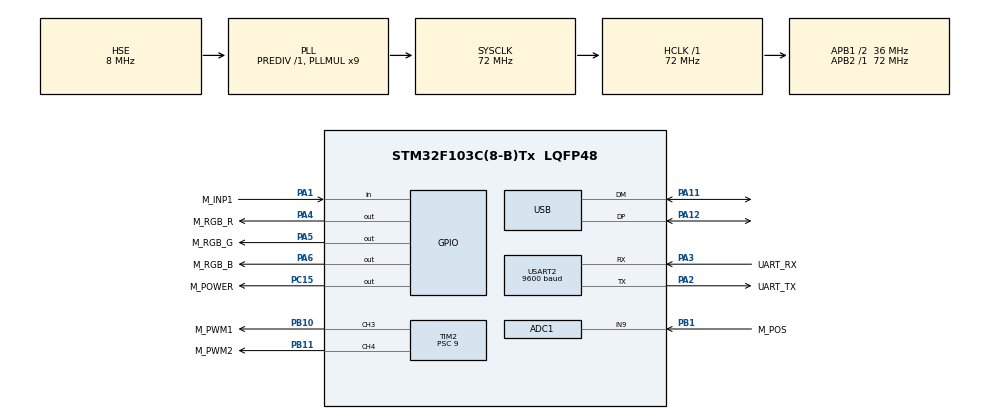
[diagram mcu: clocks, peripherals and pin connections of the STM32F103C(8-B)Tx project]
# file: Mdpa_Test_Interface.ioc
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ADC1.Channel-0\#ChannelRegularConversion=ADC_CHANNEL_9
ADC1.NbrOfConversionFlag=1
ADC1.Rank-0\#ChannelRegularConversion=1
ADC1.SamplingTime-0\#ChannelRegularConversion=ADC_SAMPLETIME_1CYCLE_5
ADC1.master=1
Dma.Request0=USART2_RX
Dma.USART2_RX.0.Direction=DMA_PERIPH_TO_MEMORY
Dma.USART2_RX.0.Instance=DMA1_Channel6
Dma.USART2_RX.0.MemDataAlignment=DMA_MDATAALIGN_BYTE
Dma.USART2_RX.0.MemInc=DMA_MINC_ENABLE
Dma.USART2_RX.0.Mode=DMA_CIRCULAR
Dma.USART2_RX.0.PeriphDataAlignment=DMA_PDATAALIGN_BYTE
Dma.USART2_RX.0.PeriphInc=DMA_PINC_DISABLE
Dma.USART2_RX.0.Priority=DMA_PRIORITY_HIGH
FREERTOS.Tasks01=defaultTask,0,128,StartDefaultTask,Default,NULL,Dynamic,NULL,NULL
Mcu.Family=STM32F1
Mcu.Name=STM32F103C(8-B)Tx
Mcu.Package=LQFP48
NVIC.ADC1_2_IRQn=true\:5\:0\:false\:false\:true\:true\:true\:true\:true
NVIC.DMA1_Channel6_IRQn=true\:5\:0\:false\:false\:true\:true\:false\:true\:true
NVIC.PriorityGroup=NVIC_PRIORITYGROUP_4
NVIC.TIM4_IRQn=true\:15\:0\:false\:false\:true\:false\:false\:true\:true
NVIC.TimeBase=TIM4_IRQn
NVIC.TimeBaseIP=TIM4
NVIC.USART2_IRQn=true\:5\:0\:false\:false\:true\:true\:true\:true\:true
NVIC.USB_LP_CAN1_RX0_IRQn=true\:5\:0\:false\:false\:true\:true\:false\:true\:true
PA1.GPIO_Label=M_INP1
PA1.GPIO_PuPd=GPIO_PULLUP
PA1.Signal=GPIO_Input
PA11.Mode=Device
PA11.Signal=USB_DM
PA12.Mode=Device
PA12.Signal=USB_DP
PA13.Mode=Serial_Wire
PA13.Signal=SYS_JTMS-SWDIO
PA14.Mode=Serial_Wire
PA14.Signal=SYS_JTCK-SWCLK
PA2.GPIO_Label=UART_TX
PA2.Mode=Asynchronous
PA2.Signal=USART2_TX
PA3.GPIO_Label=UART_RX
PA3.GPIO_PuPd=GPIO_PULLUP
PA3.Mode=Asynchronous
PA3.Signal=USART2_RX
PA4.GPIO_Label=M_RGB_R
PA4.Signal=GPIO_Output
PA5.GPIO_Label=M_RGB_G
PA5.Signal=GPIO_Output
PA6.GPIO_Label=M_RGB_B
PA6.Signal=GPIO_Output
PB1.GPIO_Label=M_POS
PB1.Signal=ADCx_IN9
PB10.GPIO_Label=M_PWM1
PB10.Signal=S_TIM2_CH3
PB11.GPIO_Label=M_PWM2
PB11.Signal=S_TIM2_CH4
PC15-OSC32_OUT.GPIO_Label=M_POWER
PC15-OSC32_OUT.Signal=GPIO_Output
PD0-OSC_IN.Mode=HSE-External-Oscillator
PD0-OSC_IN.Signal=RCC_OSC_IN
PD1-OSC_OUT.Mode=HSE-External-Oscillator
PD1-OSC_OUT.Signal=RCC_OSC_OUT
ProjectManager.HeapSize=0x200
ProjectManager.StackSize=0x400
ProjectManager.TargetToolchain=MDK-ARM V5.32
RCC.ADCPresc=RCC_ADCPCLK2_DIV6
RCC.AHBFreq_Value=72000000
RCC.APB1CLKDivider=RCC_HCLK_DIV2
RCC.APB1Freq_Value=36000000
RCC.APB1TimFreq_Value=72000000
RCC.APB2Freq_Value=72000000
RCC.APB2TimFreq_Value=72000000
RCC.HCLKFreq_Value=72000000
RCC.PLLMUL=RCC_PLL_MUL9
RCC.PLLSourceVirtual=RCC_PLLSOURCE_HSE
RCC.SYSCLKFreq_VALUE=72000000
RCC.SYSCLKSource=RCC_SYSCLKSOURCE_PLLCLK
RCC.USBFreq_Value=48000000
RCC.USBPrescaler=RCC_USBCLKSOURCE_PLL_DIV1_5
SH.ADCx_IN9.0=ADC1_IN9,IN9
SH.S_TIM2_CH3.0=TIM2_CH3,PWM Generation3 CH3
SH.S_TIM2_CH4.0=TIM2_CH4,PWM Generation4 CH4
TIM2.Channel-PWM\ Generation3\ CH3=TIM_CHANNEL_3
TIM2.Channel-PWM\ Generation4\ CH4=TIM_CHANNEL_4
TIM2.Period=359
TIM2.Prescaler=9
USART2.BaudRate=9600
USART2.VirtualMode=VM_ASYNC
USB_DEVICE.CLASS_NAME_FS=CDC
USB_DEVICE.VirtualMode=Cdc
USB_DEVICE.VirtualModeFS=Cdc_FS
VP_FREERTOS_VS_CMSIS_V1.Mode=CMSIS_V1
VP_SYS_VS_tim4.Mode=TIM4
VP_USB_DEVICE_VS_USB_DEVICE_CDC_FS.Mode=CDC_FS
board=custom

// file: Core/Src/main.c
/* USER CODE BEGIN Header */
/**
  ******************************************************************************
  * @file           : main.c
  * @brief          : Main program body
  ******************************************************************************
  * @attention
  *
  * Copyright (c) 2022 STMicroelectronics.
  * All rights reserved.
  *
  * This software is licensed under terms that can be found in the LICENSE file
  * in the root directory of this software component.
  * If no LICENSE file comes with this software, it is provided AS-IS.
  *
  ******************************************************************************
  */
/* USER CODE END Header */
#include "main.h"
#include "cmsis_os.h"
#include "adc.h"
#include "dma.h"
#include "tim.h"
#include "usart.h"
#include "usb_device.h"
#include "gpio.h"

/* USER CODE BEGIN Includes */
#include "swl_Application.h"
/* USER CODE END Includes */

/* USER CODE BEGIN PV */
uint8_t buffer[64];
/* USER CODE END PV */

void SystemClock_Config(void);
void MX_FREERTOS_Init(void);

int main(void)
{

  /* MCU Configuration--------------------------------------------------------*/

  /* Reset of all peripherals, Initializes the Flash interface and the Systick. */
	HAL_Init();

  /* Configure the system clock */
  SystemClock_Config();

  /* Initialize all configured peripherals */
  MX_GPIO_Init();
  MX_DMA_Init();
  MX_TIM2_Init();
  MX_USART2_UART_Init();
  MX_ADC1_Init();
  /* USER CODE BEGIN 2 */
  swl_InitApplication();
  /* USER CODE END 2 */

  /* Call init function for freertos objects (in freertos.c) */
  MX_FREERTOS_Init();
  /* Start scheduler */
  osKernelStart();

  /* We should never get here as control is now taken by the scheduler */
  /* Infinite loop */
  while (1)
  {

  }
}

void SystemClock_Config(void)
{
  RCC_OscInitTypeDef RCC_OscInitStruct = {0};
  RCC_ClkInitTypeDef RCC_ClkInitStruct = {0};
  RCC_PeriphCLKInitTypeDef PeriphClkInit = {0};

  /** Initializes the RCC Oscillators according to the specified parameters
  * in the RCC_OscInitTypeDef structure.
  */
  RCC_OscInitStruct.OscillatorType = RCC_OSCILLATORTYPE_HSE;
  RCC_OscInitStruct.HSEState = RCC_HSE_ON;
  RCC_OscInitStruct.HSEPredivValue = RCC_HSE_PREDIV_DIV1;
  RCC_OscInitStruct.HSIState = RCC_HSI_ON;
  RCC_OscInitStruct.PLL.PLLState = RCC_PLL_ON;
  RCC_OscInitStruct.PLL.PLLSource = RCC_PLLSOURCE_HSE;
  RCC_OscInitStruct.PLL.PLLMUL = RCC_PLL_MUL9;
  if (HAL_RCC_OscConfig(&RCC_OscInitStruct) != HAL_OK)
  {
    Error_Handler();
  }
  /** Initializes the CPU, AHB and APB buses clocks
  */
  RCC_ClkInitStruct.ClockType = RCC_CLOCKTYPE_HCLK|RCC_CLOCKTYPE_SYSCLK
                              |RCC_CLOCKTYPE_PCLK1|RCC_CLOCKTYPE_PCLK2;
  RCC_ClkInitStruct.SYSCLKSource = RCC_SYSCLKSOURCE_PLLCLK;
  RCC_ClkInitStruct.AHBCLKDivider = RCC_SYSCLK_DIV1;
  RCC_ClkInitStruct.APB1CLKDivider = RCC_HCLK_DIV2;
  RCC_ClkInitStruct.APB2CLKDivider = RCC_HCLK_DIV1;

  if (HAL_RCC_ClockConfig(&RCC_ClkInitStruct, FLASH_LATENCY_2) != HAL_OK)
  {
    Error_Handler();
  }
  PeriphClkInit.PeriphClockSelection = RCC_PERIPHCLK_ADC|RCC_PERIPHCLK_USB;
  PeriphClkInit.AdcClockSelection = RCC_ADCPCLK2_DIV6;
  PeriphClkInit.UsbClockSelection = RCC_USBCLKSOURCE_PLL_DIV1_5;
  if (HAL_RCCEx_PeriphCLKConfig(&PeriphClkInit) != HAL_OK)
  {
    Error_Handler();
  }
}

void HAL_TIM_PeriodElapsedCallback(TIM_HandleTypeDef *htim)
{
  if (htim->Instance == TIM4) {
    HAL_IncTick();
  }
}

void Error_Handler(void)
{
  __disable_irq();
  while (1)
  {
  }
}

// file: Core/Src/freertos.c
/* USER CODE BEGIN Header */
/**
  ******************************************************************************
  * File Name          : freertos.c
  * Description        : Code for freertos applications
  ******************************************************************************
  * @attention
  *
  * Copyright (c) 2022 STMicroelectronics.
  * All rights reserved.
  *
  * This software is licensed under terms that can be found in the LICENSE file
  * in the root directory of this software component.
  * If no LICENSE file comes with this software, it is provided AS-IS.
  *
  ******************************************************************************
  */
/* USER CODE END Header */

#include "FreeRTOS.h"
#include "task.h"
#include "main.h"
#include "cmsis_os.h"

osThreadId defaultTaskHandle;

void StartDefaultTask(void const * argument);

extern void MX_USB_DEVICE_Init(void);
void MX_FREERTOS_Init(void); /* (MISRA C 2004 rule 8.1) */

/* GetIdleTaskMemory prototype (linked to static allocation support) */
void vApplicationGetIdleTaskMemory( StaticTask_t **ppxIdleTaskTCBBuffer, StackType_t **ppxIdleTaskStackBuffer, uint32_t *pulIdleTaskStackSize );

/* USER CODE BEGIN GET_IDLE_TASK_MEMORY */
static StaticTask_t xIdleTaskTCBBuffer;
static StackType_t xIdleStack[configMINIMAL_STACK_SIZE];

void vApplicationGetIdleTaskMemory( StaticTask_t **ppxIdleTaskTCBBuffer, StackType_t **ppxIdleTaskStackBuffer, uint32_t *pulIdleTaskStackSize )
{
  *ppxIdleTaskTCBBuffer = &xIdleTaskTCBBuffer;
  *ppxIdleTaskStackBuffer = &xIdleStack[0];
  *pulIdleTaskStackSize = configMINIMAL_STACK_SIZE;
  /* place for user code */
}
/* USER CODE END GET_IDLE_TASK_MEMORY */

void MX_FREERTOS_Init(void) {

  /* Create the thread(s) */
  /* definition and creation of defaultTask */
  osThreadDef(defaultTask, StartDefaultTask, osPriorityNormal, 0, 128);
  defaultTaskHandle = osThreadCreate(osThread(defaultTask), NULL);

}

void StartDefaultTask(void const * argument)
{
  /* init code for USB_DEVICE */
  MX_USB_DEVICE_Init();
  for(;;)
  {
    osDelay(1);
  }
}
